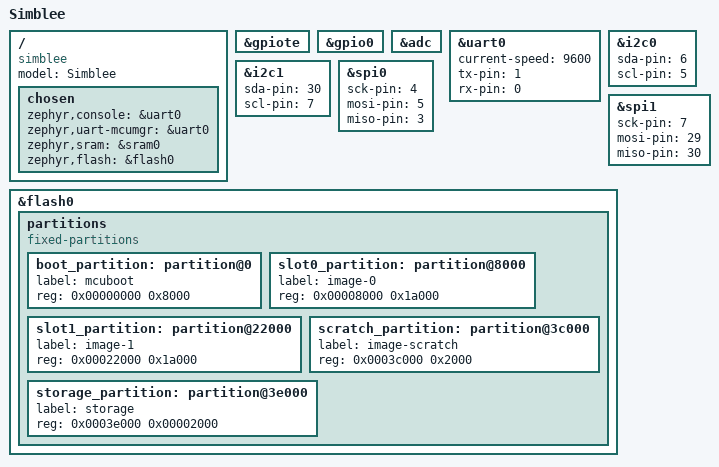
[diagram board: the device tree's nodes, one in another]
/*
 * Copyright (c) 2017 Linaro Limited
 *
 * SPDX-License-Identifier: Apache-2.0
 */

/dts-v1/;
#include <nordic/nrf51822_cfac.dtsi>

/ {
	model = "Simblee";
	compatible = "simblee", "nordic,nrf51822";

	chosen {
		zephyr,console = &uart0;
		zephyr,uart-mcumgr = &uart0;
		zephyr,sram = &sram0;
		zephyr,flash = &flash0;
	};
};

&gpiote {
	status ="ok";
};

&gpio0 {
	status ="ok";
};

&adc {
	status ="ok";
};

&uart0 {
	current-speed = <9600>;
	status = "ok";
	tx-pin = <1>;
	rx-pin = <0>;
};

&i2c0 {
        status = "ok";
        sda-pin = <6>;
        scl-pin = <5>;
};

&i2c1 {
        status = "ok";
        sda-pin = <30>;
        scl-pin = <7>;
};

&spi0 {
	status = "ok";
	sck-pin = <4>;
	mosi-pin = <5>;
	miso-pin = <3>;
};

&spi1 {
        status = "ok";
        sck-pin = <7>;
        mosi-pin = <29>;
        miso-pin = <30>;
};

&flash0 {
	/*
	 * For more information, see:
	 * http://docs.zephyrproject.org/latest/devices/dts/flash_partitions.html
	 */
	partitions {
		compatible = "fixed-partitions";
		#address-cells = <1>;
		#size-cells = <1>;

		boot_partition: partition@0 {
			label = "mcuboot";
			reg = <0x00000000 0x8000>;
		};
		slot0_partition: partition@8000 {
			label = "image-0";
			reg = <0x00008000 0x1a000>;
		};
		slot1_partition: partition@22000 {
			label = "image-1";
			reg = <0x00022000 0x1a000>;
		};
		scratch_partition: partition@3c000 {
			label = "image-scratch";
			reg = <0x0003c000 0x2000>;
		};
		storage_partition: partition@3e000 {
			label = "storage";
			reg = <0x0003e000 0x00002000>;
		};
	};
};
